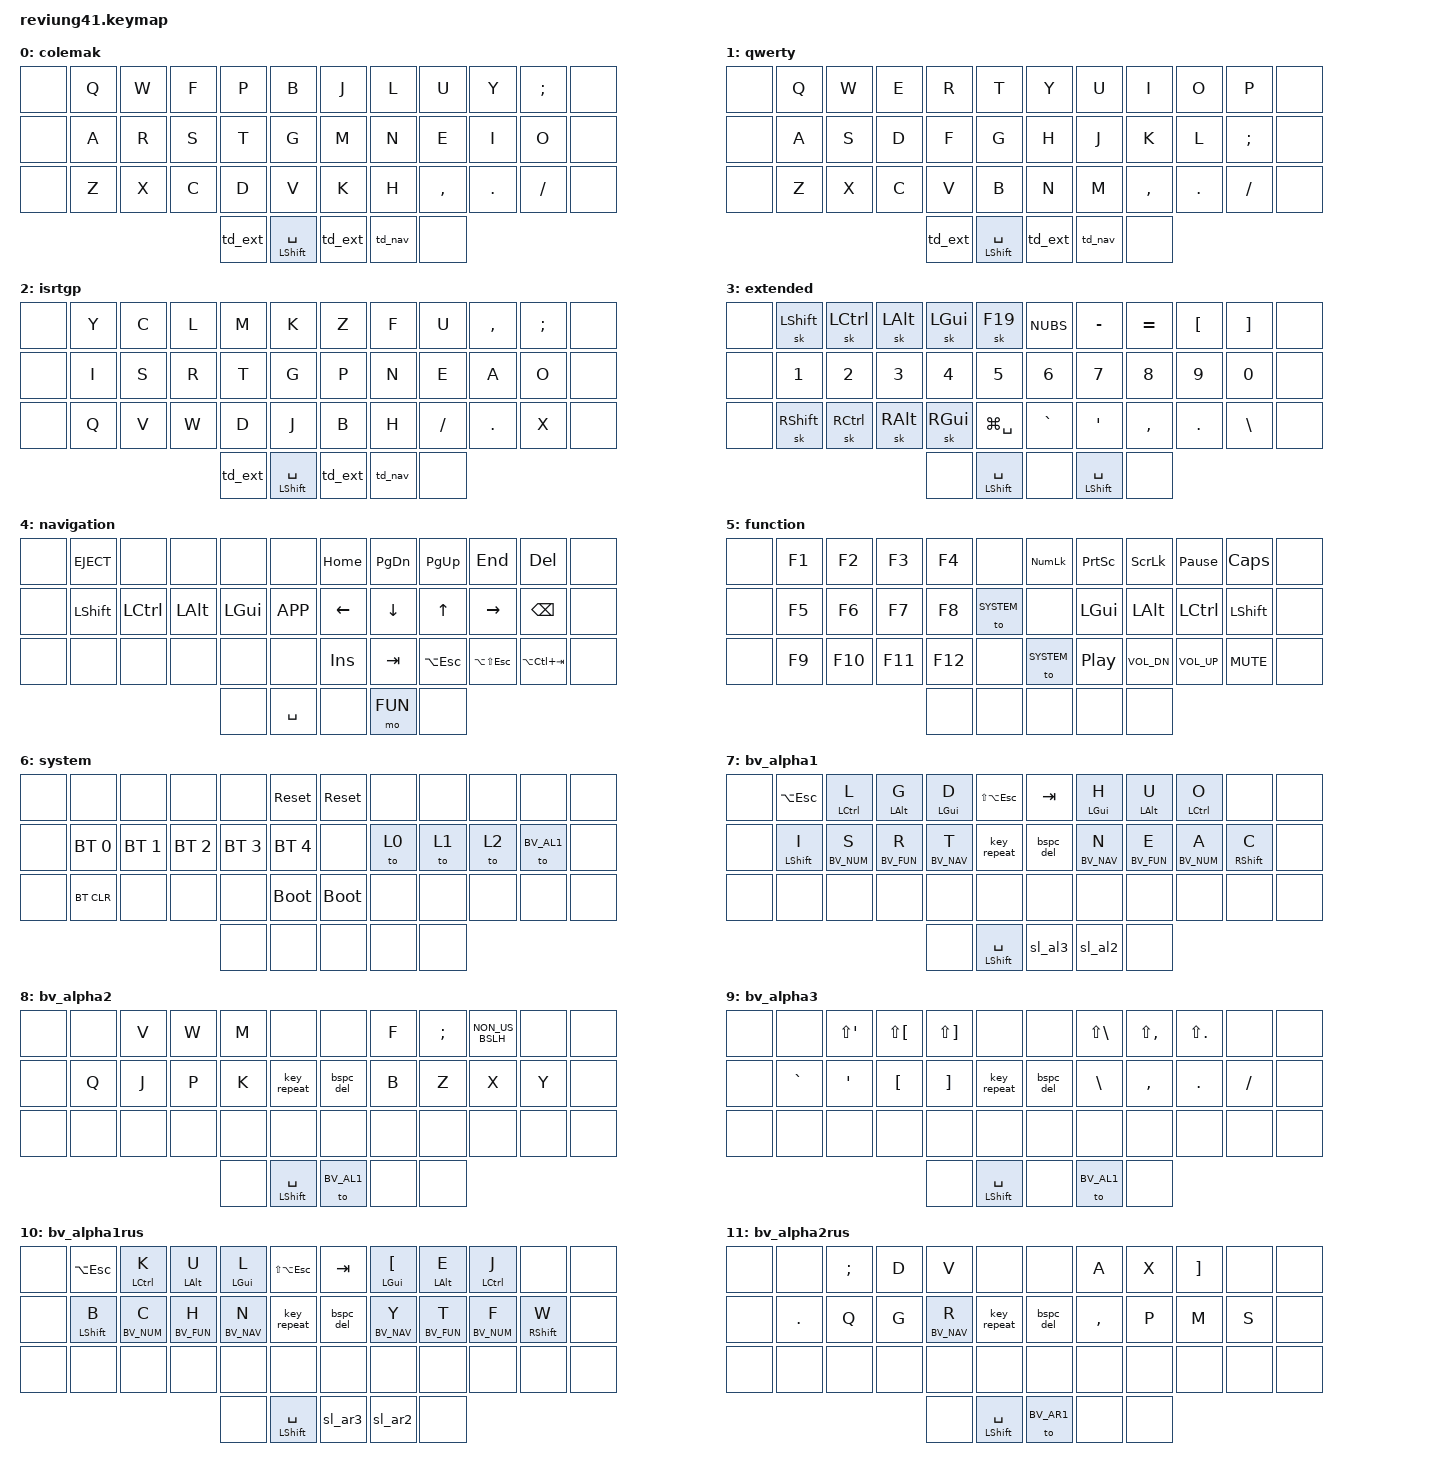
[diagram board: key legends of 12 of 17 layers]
/*
* Copyright (c) 2020 The ZMK Contributors
*
* SPDX-License-Identifier: MIT
*/

#include <behaviors.dtsi>
#include <dt-bindings/zmk/keys.h>
#include <dt-bindings/zmk/bt.h>

// Layers
#define COLEMAK 0
#define QWERTY  1
#define ISRT    2
#define EXT     3
#define NAV     4
#define FUN     5
#define SYSTEM  6

#define BV_AL1   7
#define BV_AL2   8
#define BV_AL3   9
#define BV_AR1   10
#define BV_AR2   11
#define BV_AR3   12
#define BV_NUM   13
#define BV_NAV   14
#define BV_FUN   15
#define BV_MED   16

// Bindings
#define _____ &none
#define SHFTSPC &rt LSHFT SPC 
#define HYPER LA(LG(LCTRL)) 0
// tapping-term-ms = <300>;
#define TAPPING_TERM 300 
// timeout-ms = <30>;
#define COMBO_TIMEOUT 40

#ifndef NUBS
  #define NUBS NON_US_BSLH
#endif

#define KP_STAR KP_ASTERISK

#ifndef KP_NUM
  #define KP_NUM KP_NUMLOCK
#endif

&sk {
    release-after-ms = <1500>;
    quick-release;
};

&mt {
    tapping-term-ms = <200>;
    quick-tap-ms = <200>;
    flavor = "tap-preferred";
 };

/ {
    combos {
        compatible = "zmk,combos";
        lock {
            bindings = <&kp LG(L)>;
            key-positions = < 11 23 35 >;
            timeout-ms = < COMBO_TIMEOUT >;
        };

        left_escape {
            bindings = <&kp ESC>;
            key-positions = <2 3>;
            timeout-ms = < COMBO_TIMEOUT >;
            layers = < COLEMAK QWERTY ISRT >;
        };
        left_enter {
            bindings = <&kp ENTER>;
            key-positions = <14 15>;
            timeout-ms = < COMBO_TIMEOUT >;
            layers = < COLEMAK QWERTY ISRT >;
        };
        right_escape {
            bindings = <&kp ESC>;
            key-positions = <8 9>;
            timeout-ms = < COMBO_TIMEOUT >;
            layers = < COLEMAK QWERTY ISRT >;
        };
        right_enter {
            bindings = <&kp ENTER>;
            key-positions = <20 21>;
            timeout-ms = < COMBO_TIMEOUT >;
            layers = < COLEMAK QWERTY ISRT >;
        };

        to_qwerty { 
            bindings = <&to QWERTY>;
            key-positions = < 2 3 4 >;
            timeout-ms = < COMBO_TIMEOUT >;
        };
        to_colemak { 
            bindings = <&to COLEMAK>;
            key-positions = < 7 8 9 >;
            timeout-ms = < COMBO_TIMEOUT >;
        };        

        bv_to_eng { 
            bindings = <&to_eng>;
            key-positions = < 14 15 16 >;
            timeout-ms = < COMBO_TIMEOUT >;
        };
        bv_to_rus {
            bindings = <&to_rus>;
            key-positions = < 19 20 21 >;
            timeout-ms = < COMBO_TIMEOUT >;
            layers = < BV_AL1 BV_AR1 >;
        };    

        bv_escape {
            bindings = <&kp ESC>;
            key-positions = <8 9>;
            timeout-ms = < COMBO_TIMEOUT >;
            layers = < BV_AL1 BV_AR1 >;
        };
        bv_escape_left {
            bindings = <&kp ESC>;
            key-positions = <2 3>;
            timeout-ms = < COMBO_TIMEOUT >;
            layers = < BV_AL1 BV_AR1 >;
        };
        bv_enter {
            bindings = <&kp ENTER>;
            key-positions = <20 21>;
            timeout-ms = < COMBO_TIMEOUT >;
            layers = < BV_AL1 BV_AR1 >;
        };
        bv_backspace {
            bindings = <&kp BACKSPACE>;
            key-positions = <19 20>;
            timeout-ms = < COMBO_TIMEOUT >;
            layers = < BV_AL1 BV_AR1 >;
        };
        bv_tab {
            bindings = <&kp TAB>;
            key-positions = <7 8>;
            timeout-ms = < COMBO_TIMEOUT >;
            layers = < BV_AL1 BV_AR1 >;
        };

        bv_bt0 {
            bindings = <&bt BT_SEL 0>;
            key-positions = <0 14 26>;
            timeout-ms = < COMBO_TIMEOUT >;
        };
        bv_bt1 {
            bindings = <&bt BT_SEL 1>;
            key-positions = <0 5 27>;
            timeout-ms = < COMBO_TIMEOUT >;
        };
        bv_bt2 {
            bindings = <&bt BT_SEL 2>;
            key-positions = <0 16 28>;
            timeout-ms = < COMBO_TIMEOUT >;
        };
        bv_bt3 {
            bindings = <&bt BT_SEL 3>;
            key-positions = <0 19 31>;
            timeout-ms = < COMBO_TIMEOUT >;
        };
        bv_bt4 {
            bindings = <&bt BT_SEL 4>;
            key-positions = <0 20 32>;
            timeout-ms = < COMBO_TIMEOUT >;
        };
        bv_bt_clr {
            bindings = <&bt BT_CLR>;
            key-positions = <0 21 33>;
            timeout-ms = < COMBO_TIMEOUT >;
        };        
    };

    macros {
        ext_shifted: ext_shifted {
            label = "ext_shifted";
            compatible = "zmk,behavior-macro";
            #binding-cells = <0>;
            wait-ms = <0>;
            bindings =
                <&macro_press>,
                <&mo EXT &kp LSHFT>,
                <&macro_pause_for_release>,
                <&macro_release>,
                <&mo EXT &kp LSHFT>;
        };

        to_eng: to_eng {
             label = "to_eng";
             compatible = "zmk,behavior-macro";
             #binding-cells = <0>;
             bindings = <&to BV_AL1 &kp LA(LC(LG(N1)))>;
         };
         to_rus: to_rus {
             label = "to_rus";
             compatible = "zmk,behavior-macro";
             #binding-cells = <0>;
             bindings = <&to BV_AR1 &kp LA(LC(LG(N3)))>;
         };
        sl_al2: sl_al2 {
            label = "sl_al2";
            compatible = "zmk,behavior-macro";
            #binding-cells = <0>;
            wait-ms = <0>;
            bindings = <&sl BV_AL2>;
        };
        sl_al3: sl_al3 {
            label = "sl_al3";
            compatible = "zmk,behavior-macro";
            #binding-cells = <0>;
            wait-ms = <0>;
            bindings = <&sl BV_AL3>;
        };
        sl_ar2: sl_ar2 {
            label = "sl_ar2";
            compatible = "zmk,behavior-macro";
            #binding-cells = <0>;
            wait-ms = <0>;
            bindings = <&sl BV_AR2>;
        };
        sl_ar3: sl_ar3 {
            label = "sl_ar3";
            compatible = "zmk,behavior-macro";
            #binding-cells = <0>;
            wait-ms = <0>;
            bindings = <&sl BV_AR3>;
        };
    };

    behaviors {
        td_nav: tap_dance_nav {
            compatible = "zmk,behavior-tap-dance";
            label = "TAP_DANCE_NAV";
            #binding-cells = <0>;
            tapping-term-ms = <300>;
            bindings =
                <&mo NAV>,
                <&mo FUN>;
        };
        td_ext: tap_dance_ext {
            compatible = "zmk,behavior-tap-dance";
            label = "TAP_DANCE_EXT";
            #binding-cells = <0>;
            tapping-term-ms = <300>;
            bindings =
                <&mo EXT>,
                <&ext_shifted>;
        };

        mtl: left_hand_positional_hold_tap {
            compatible = "zmk,behavior-hold-tap";
            label = "LEFT_POSITIONAL_HOLD_TAP";
            #binding-cells = <2>;
            flavor = "balanced";
            tapping-term-ms = < TAPPING_TERM >;
            quick-tap-ms = <200>;
            bindings = <&kp>, <&kp>;
            hold-trigger-key-positions = < 6 7 8 9 10 11 18 19 20 21 22 23 30 31 32 33 34 35 36 37 38 39 40>;    // <---[[right-hand keys]]
        };
        mtr: right_hand_positional_hold_tap {
            compatible = "zmk,behavior-hold-tap";
            label = "RIGHT_POSITIONAL_HOLD_TAP";
            #binding-cells = <2>;
            flavor = "balanced";
            tapping-term-ms = < TAPPING_TERM >;
            quick-tap-ms = <200>;
            bindings = <&kp>, <&kp>;
            hold-trigger-key-positions = < 0 1 2 3 4 5 12 13 14 15 16 17 24 25 26 27 28 29 36 37 38 39 40 >;    // <---[[left-hand keys]]
        };
    
        mol: homerow_layers_left {
            compatible = "zmk,behavior-hold-tap";
            label = "HOMEROW_LAYERS_L";
            #binding-cells = <2>;
            tapping-term-ms = < TAPPING_TERM >;
            quick-tap-ms = <200>;
            // global-quick-tap;
            flavor = "tap-preferred";
            bindings = <&mo>, <&kp>;
            hold-trigger-key-positions = < 6 7 8 9 10 11 18 19 20 21 22 23 30 31 32 33 34 35 36 37 38 39 40>;    // <---[[right-hand keys]]
        };
        mor: homerow_layers_right {
            compatible = "zmk,behavior-hold-tap";
            label = "HOMEROW_LAYERS_R";
            #binding-cells = <2>;
            tapping-term-ms = < TAPPING_TERM >;
            quick-tap-ms = <200>;
            // global-quick-tap;
            flavor = "tap-preferred";
            bindings = <&mo>, <&kp>;
            hold-trigger-key-positions = < 0 1 2 3 4 5 12 13 14 15 16 17 24 25 26 27 28 29 36 37 38 39 40 >;    // <---[[left-hand keys]]
        };

        hrep: hyper_repeat {
            compatible = "zmk,behavior-hold-tap";
            label = "HYPER_REPEAT";
            #binding-cells = <2>;
            flavor = "hold-preferred";
            tapping-term-ms = < TAPPING_TERM >;
            quick-tap-ms = <200>;
            bindings = <&kp>, <&key_repeat>;
        };

        rt: rt {
            compatible = "zmk,behavior-hold-tap";
            label = "retro-mod-tap";
            #binding-cells = <2>;
            flavor = "balanced";
            tapping-term-ms = < TAPPING_TERM >;
            quick-tap-ms = <200>;
            bindings = <&kp>, <&kp>;
            retro-tap;
        };

        bspc_del: backspace_delete {
            compatible = "zmk,behavior-mod-morph";
            label = "BACKSPACE_DELETE";
            #binding-cells = <0>;
            bindings = <&kp BACKSPACE>, <&kp DELETE>;
            mods = <(MOD_LSFT|MOD_RSFT)>;
        };
    };

    keymap {
        compatible = "zmk,keymap";

        colemak {
            bindings = <
_____  &kp Q         &kp W     &kp F      &kp P           &kp B              &kp J       &kp L           &kp U        &kp Y    &kp SEMI     _____
_____  &kp A         &kp R     &kp S      &kp T           &kp G              &kp M       &kp N           &kp E        &kp I    &kp O        _____
_____  &kp Z         &kp X     &kp C      &kp D           &kp V              &kp K       &kp H           &kp COMMA    &kp DOT  &kp FSLH     _____
                                          &td_ext           &rt LSHFT SPC   &td_ext   &td_nav     _____
            >;
        };

        qwerty {
            bindings = <
_____  &kp Q         &kp W     &kp E      &kp R           &kp T              &kp Y       &kp U           &kp I        &kp O    &kp P        _____
_____  &kp A         &kp S     &kp D      &kp F           &kp G              &kp H       &kp J           &kp K        &kp L    &kp SEMI     _____
_____  &kp Z         &kp X     &kp C      &kp V           &kp B              &kp N       &kp M           &kp COMMA    &kp DOT  &kp FSLH     _____
                                          &td_ext           &rt LSHFT SPC   &td_ext   &td_nav     _____
            >;
        };

        isrtgp {
            bindings = <
_____  &kp Y         &kp C     &kp L      &kp M           &kp K              &kp Z       &kp F           &kp U        &kp COMMA &kp SEMI    _____
_____  &kp I         &kp S     &kp R      &kp T           &kp G              &kp P       &kp N           &kp E        &kp A     &kp O       _____
_____  &kp Q         &kp V     &kp W      &kp D           &kp J              &kp B       &kp H           &kp FSLH     &kp DOT   &kp X       _____
                                          &td_ext           &rt LSHFT SPC    &td_ext   &td_nav     _____
            >;
        };
        
        extended {
            bindings = <
_____  &sk LSHFT     &sk LCTRL &sk LALT   &sk LGUI        &sk F19            &kp NUBS    &kp MINUS       &kp EQUAL    &kp LBKT  &kp RBKT      _____
_____  &kp N1        &kp N2    &kp N3     &kp N4          &kp N5             &kp N6      &kp N7          &kp N8       &kp N9    &kp N0        _____
_____  &sk RSHFT     &sk RCTRL &sk RALT   &sk RGUI        &kp LG(SPACE)      &kp GRAVE   &kp SQT         &kp COMMA    &kp DOT   &kp BSLH      _____
                                          _____           &rt LSHFT SPC    _____    &rt LSHFT SPC   _____
            >;
        };

        navigation {
            bindings = <
_____  &kp C_EJECT   &none     &none      &none           &none              &kp HOME    &kp PG_DN       &kp PG_UP    &kp END          &kp DEL         _____
_____  &kp LSHFT     &kp LCTRL &kp LALT   &kp LGUI        &kp K_APP          &kp LEFT    &kp DOWN        &kp UP       &kp RIGHT        &kp BSPC        _____
_____  &none         &none     &none      &none           &none              &kp INS     &kp TAB         &kp LA(ESC)  &kp LA(LS(ESC))  &kp LA(LC(TAB)) _____
                                _____     &kp SPACE       _____              &mo FUN      _____
            >;
        };

        function {
            bindings = <
_____  &kp F1        &kp F2    &kp F3     &kp F4          &none              &kp KP_NUM  &kp PRINTSCREEN   &kp SCROLLLOCK  &kp PAUSE_BREAK  &kp CAPS        _____
_____  &kp F5        &kp F6    &kp F7     &kp F8          &to SYSTEM         &none       &kp LGUI          &kp LALT        &kp LCTRL        &kp LSHFT       _____
_____  &kp F9        &kp F10   &kp F11    &kp F12         &none              &to SYSTEM  &kp C_PLAY_PAUSE  &kp C_VOL_DN    &kp C_VOL_UP     &kp C_MUTE      _____
                                _____     _____           _____              _____       _____
            >;
        };

        system {
            bindings = <
_____  &none         &none        &none        &none        &sys_reset       &sys_reset  &none          &none        &none        &none      _____
_____  &bt BT_SEL 0  &bt BT_SEL 1 &bt BT_SEL 2 &bt BT_SEL 3 &bt BT_SEL 4     &none       &to 0          &to 1        &to 2        &to BV_AL1 _____
_____  &bt BT_CLR    &none        &none        &none        &bootloader      &bootloader &none          &none        &none        &none      _____
                                _____          _____        _____            _____       _____
            >;
        };

// --------------------------------------------------------------------------------------------------------------------------------------------
// Ben Vallack 18-keys layout
// --------------------------------------------------------------------------------------------------------------------------------------------

        bv_alpha1 {
            bindings = <
        _____        &kp LA(ESC)       &mtl LCTL L        &mtl LALT G   &mtl LGUI D  &kp LS(LA(ESC))   &kp TAB      &mtr LGUI H       &mtr LALT U     &mtr LCTL O      _____       _____
        _____        &mtl LSHFT I      &mol BV_NUM S      &mol BV_FUN R &mol BV_NAV T &key_repeat      &bspc_del    &mor BV_NAV N     &mor BV_FUN E   &mor BV_NUM A    &mtr RSHFT C        _____
        _____        _____             _____              _____         _____         _____            _____        _____             _____           _____            _____        _____
                                                            _____       &rt LSHFT SPC  &sl_al3      &sl_al2 _____
            >;
        };
        bv_alpha2 {
            bindings = <
        _____        _____             &kp V              &kp W         &kp M         _____            _____        &kp F             &kp SEMI        &kp NON_US_BSLH  _____        _____
        _____        &kp Q             &kp J              &kp P         &kp K         &key_repeat      &bspc_del    &kp B             &kp Z           &kp X            &kp Y        _____
        _____        _____             _____              _____         _____         _____            _____        _____             _____           _____            _____        _____
                                                                _____   &mt LSHFT SPC  &to BV_AL1   _____   _____
            >;
        };
        bv_alpha3 {
            bindings = <
        _____        _____             &kp LS(SQT)        &kp LS(LBKT)  &kp LS(RBKT)  _____            _____        &kp LS(BSLH)      &kp LS(COMMA)   &kp LS(DOT)      _____        _____
        _____        &kp GRAVE         &kp SQT            &kp LBKT      &kp RBKT      &key_repeat      &bspc_del    &kp BSLH          &kp COMMA       &kp DOT          &kp FSLH        _____
        _____        _____             _____              _____         _____         _____            _____        _____             _____           _____            _____        _____
                                                                 _____  &mt LSHFT SPC  _____        &to BV_AL1 _____
            >;
        };

        bv_alpha1rus {
            bindings = <
        _____        &kp LA(ESC)       &mtl LCTL K        &mtl LALT U   &mtl LGUI L   &kp LS(LA(ESC))  &kp TAB      &mtr LGUI LBKT    &mtr LALT E     &mtr LCTL J      _____        _____
        _____        &mtl LSHFT B      &mol BV_NUM C      &mol BV_FUN H &mol BV_NAV N &key_repeat      &bspc_del    &mor BV_NAV Y     &mor BV_FUN T   &mor BV_NUM F    &mtr RSHFT W        _____
        _____        _____             _____              _____         _____         _____            _____        _____             _____           _____            _____        _____
                                                                _____   &mt LSHFT SPC  &sl_ar3      &sl_ar2 _____
            >;
        };
        bv_alpha2rus {
            bindings = <
        _____        _____             &kp SEMI           &kp D         &kp V         _____            _____        &kp A             &kp X           &kp RBKT         _____        _____
        _____        &kp DOT           &kp Q              &kp G         &mol BV_NAV R &key_repeat      &bspc_del    &kp COMMA         &kp P           &kp M            &kp S        _____
        _____        _____             _____              _____         _____         _____            _____        _____             _____           _____            _____        _____
                                                                _____   &mt LSHFT SPC  &to BV_AR1   _____  _____
            >;
        };
        bv_alpha3rus {
            bindings = <
        _____        _____             _____              _____         _____         _____            _____        &kp NON_US_BSLH   _____           _____            _____        _____
        _____        &kp GRAVE         &kp SQT            &kp I         &kp O         &key_repeat      &bspc_del    &kp BSLH          &kp LS(FSLH)    &kp FSLH         &kp Z        _____
        _____        _____             _____              _____         _____         _____            _____        _____             _____           _____            _____        _____
                                                                _____   &mt LSHFT SPC _____        &to BV_AR1  _____
            >;
        };

        bv_numbers {
            bindings = <
        _____        _____          &kp KP_DIVIDE     &kp KP_PLUS       &kp N5        _____            _____        &kp N6            &kp MINUS       &kp EQUAL        _____        _____
        _____        &kp N1         &kp N2            &kp N3            &kp N4        &kp N5           &kp N6       &kp N7            &kp N8          &kp N9           &kp N0        _____
        _____        _____          _____             _____             _____         _____            _____        _____             _____           _____            _____        _____
                                                                _____  &mt LSHFT SPC &kp RALT         &kp COMMA    &kp DOT
            >;
        };

        bv_navigation {
            bindings = <
        _____        _____             &kp LCTL           &kp LALT      &kp LGUI      _____            _____        &kp PG_DN         &kp UP          &kp PG_UP        _____        _____
        _____        &kp LSHFT         &kp TAB            &kp HOME      &kp END       _____            _____        &kp LEFT          &kp DOWN        &kp RIGHT        &bspc_del        _____
        _____        _____             _____              _____         _____         _____            _____        _____             _____           _____            _____        _____
                                                                _____   &mt LSHFT SPC   _____        &mt LSHFT SPC _____
            >;
        };

        bv_function {
            bindings = <
        _____        _____             &kp LCTL           &kp LALT      &mtl LGUI F5  _____            _____        &mtr LGUI F6      &mtr LALT F11   &mtr LCTL F12    _____        _____
        _____        &mtl LSHFT F1     &kp F2             &kp F3        &kp F4        _____            _____        &kp F7            &kp F8          &kp F9           &mtr RSHFT F10        _____
        _____        _____             _____              _____         _____         _____            _____        _____             _____           _____            _____       _____
                                                                _____   &kp LSHFT     &kp PRINTSCREEN  &mo BV_MED   &kp C_EJECT 
            >;
        };
        bv_media {
            bindings = <
        _____        _____             _____              _____         &kp F5        _____            _____        &kp F6            &kp C_VOL_DN    &kp C_VOL_UP     _____        _____
        _____        &kp C_BRI_DN      &kp C_BRI_UP       &kp F3        &kp F4        _____            _____        &kp C_PREV        &kp C_PP        &kp C_NEXT       &kp C_MUTE        _____
        _____        _____             _____              _____         _____         _____            _____        _____             _____           _____            _____        _____
                                                                   _____         _____  _____  _____      &bootloader                                                                      
            >;
        };
    };
};
